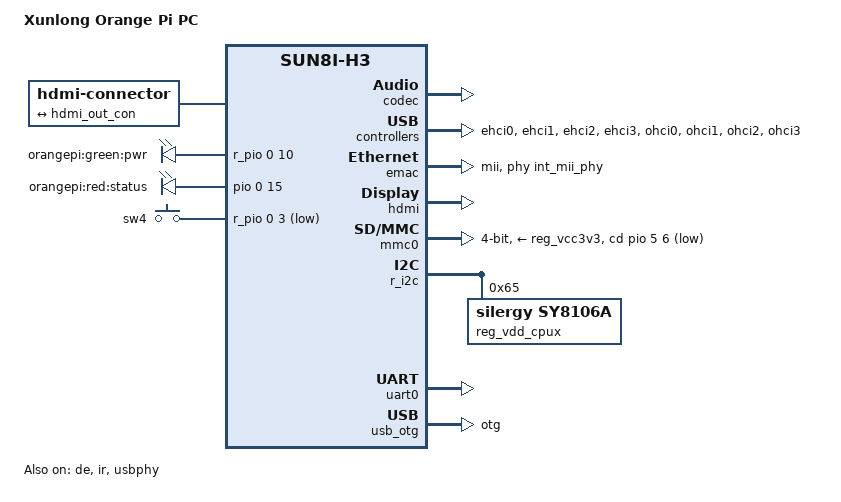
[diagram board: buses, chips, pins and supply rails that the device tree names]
/dts-v1/;
#include "sun8i-h3.dtsi"
#include "sunxi-common-regulators.dtsi"
#include <dt-bindings/gpio/gpio.h>
#include <dt-bindings/input/input.h>
/ {
	model = "Xunlong Orange Pi PC";
	compatible = "xunlong,orangepi-pc", "allwinner,sun8i-h3";
	aliases {
		ethernet0 = &emac;
		serial0 = &uart0;
	};
	chosen {
		stdout-path = "serial0:115200n8";
	};
	connector {
		compatible = "hdmi-connector";
		type = "a";
		port {
			hdmi_con_in: endpoint {
				remote-endpoint = <&hdmi_out_con>;
			};
		};
	};
	leds {
		compatible = "gpio-leds";
		pwr_led {
			label = "orangepi:green:pwr";
			gpios = <&r_pio 0 10 GPIO_ACTIVE_HIGH>;
			default-state = "on";
		};
		status_led {
			label = "orangepi:red:status";
			gpios = <&pio 0 15 GPIO_ACTIVE_HIGH>;
		};
	};
	gpio-keys {
		compatible = "gpio-keys";
		switch-4 {
			label = "sw4";
			linux,code = <KEY_POWER>;
			gpios = <&r_pio 0 3 GPIO_ACTIVE_LOW>;
			wakeup-source;
		};
	};
};
&codec {
	allwinner,audio-routing =
		"Line Out", "LINEOUT",
		"MIC1", "Mic",
		"Mic",  "MBIAS";
	status = "okay";
};
&de {
	status = "okay";
};
&cpu0 {
	cpu-supply = <&reg_vdd_cpux>;
};
&ehci0 {
	status = "okay";
};
&ehci1 {
	status = "okay";
};
&ehci2 {
	status = "okay";
};
&ehci3 {
	status = "okay";
};
&emac {
	phy-handle = <&int_mii_phy>;
	phy-mode = "mii";
	allwinner,leds-active-low;
	status = "okay";
};
&hdmi {
	status = "okay";
};
&hdmi_out {
	hdmi_out_con: endpoint {
		remote-endpoint = <&hdmi_con_in>;
	};
};
&ir {
	pinctrl-names = "default";
	pinctrl-0 = <&r_ir_rx_pin>;
	status = "okay";
};
&mmc0 {
	vmmc-supply = <&reg_vcc3v3>;
	bus-width = <4>;
	cd-gpios = <&pio 5 6 GPIO_ACTIVE_LOW>;  
	status = "okay";
};
&ohci0 {
	status = "okay";
};
&ohci1 {
	status = "okay";
};
&ohci2 {
	status = "okay";
};
&ohci3 {
	status = "okay";
};
&r_i2c {
	status = "okay";
	reg_vdd_cpux: regulator@65 {
		compatible = "silergy,sy8106a";
		reg = <0x65>;
		regulator-name = "vdd-cpux";
		silergy,fixed-microvolt = <1200000>;
		regulator-min-microvolt = <1000000>;
		regulator-max-microvolt = <1300000>;
		regulator-boot-on;
		regulator-always-on;
	};
};
&reg_usb0_vbus {
	gpio = <&r_pio 0 2 GPIO_ACTIVE_HIGH>;  
	status = "okay";
};
&uart0 {
	pinctrl-names = "default";
	pinctrl-0 = <&uart0_pa_pins>;
	status = "okay";
};
&uart1 {
	pinctrl-names = "default";
	pinctrl-0 = <&uart1_pins>;
	status = "disabled";
};
&uart2 {
	pinctrl-names = "default";
	pinctrl-0 = <&uart2_pins>;
	status = "disabled";
};
&uart3 {
	pinctrl-names = "default";
	pinctrl-0 = <&uart3_pins>;
	status = "disabled";
};
&usb_otg {
	dr_mode = "otg";
	status = "okay";
};
&usbphy {
	usb0_id_det-gpios = <&pio 6 12 GPIO_ACTIVE_HIGH>;  
	usb0_vbus-supply = <&reg_usb0_vbus>;
	status = "okay";
};
